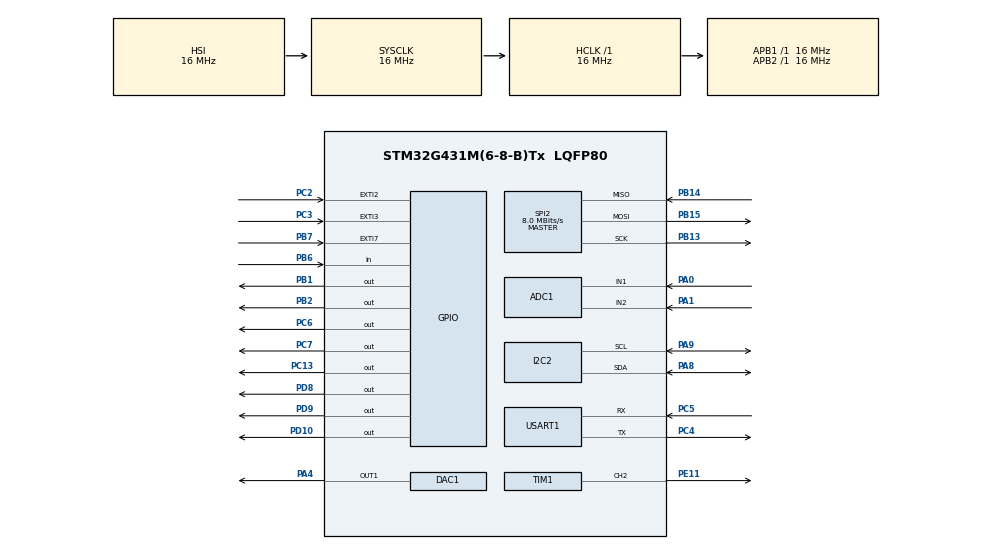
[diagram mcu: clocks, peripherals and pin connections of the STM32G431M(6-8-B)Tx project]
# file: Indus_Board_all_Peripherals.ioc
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ADC1.Channel-0\#ChannelRegularConversion=ADC_CHANNEL_1
ADC1.NbrOfConversionFlag=1
ADC1.OffsetNumber-0\#ChannelRegularConversion=ADC_OFFSET_NONE
ADC1.Rank-0\#ChannelRegularConversion=1
ADC1.SamplingTime-0\#ChannelRegularConversion=ADC_SAMPLETIME_2CYCLES_5
ADC1.master=1
Mcu.Family=STM32G4
Mcu.Name=STM32G431M(6-8-B)Tx
Mcu.Package=LQFP80
NVIC.EXTI2_IRQn=true\:0\:0\:false\:false\:true\:true\:true\:true
NVIC.EXTI3_IRQn=true\:0\:0\:false\:false\:true\:true\:true\:true
NVIC.EXTI9_5_IRQn=true\:0\:0\:false\:false\:true\:true\:true\:true
NVIC.PriorityGroup=NVIC_PRIORITYGROUP_4
NVIC.USART1_IRQn=true\:0\:0\:false\:false\:true\:true\:true\:true
PA0.Mode=IN1-Single-Ended
PA0.Signal=ADC1_IN1
PA1.Mode=IN2-Single-Ended
PA1.Signal=ADC1_IN2
PA13.Mode=JTAG_4_pins
PA13.Signal=SYS_JTMS-SWDIO
PA14.Mode=JTAG_4_pins
PA14.Signal=SYS_JTCK-SWCLK
PA15.Mode=JTAG_4_pins
PA15.Signal=SYS_JTDI
PA4.Signal=COMP_DAC11_group
PA8.Mode=I2C
PA8.Signal=I2C2_SDA
PA9.Mode=I2C
PA9.Signal=I2C2_SCL
PB1.Signal=GPIO_Output
PB13.Mode=Full_Duplex_Master
PB13.Signal=SPI2_SCK
PB14.Mode=Full_Duplex_Master
PB14.Signal=SPI2_MISO
PB15.Mode=Full_Duplex_Master
PB15.Signal=SPI2_MOSI
PB2.Signal=GPIO_Output
PB3.Mode=JTAG_4_pins
PB3.Signal=SYS_JTDO-SWO
PB6.Signal=GPIO_Input
PB7.Signal=GPXTI7
PC13.Signal=GPIO_Output
PC2.Signal=GPXTI2
PC3.Signal=GPXTI3
PC4.Mode=Asynchronous
PC4.Signal=USART1_TX
PC5.Mode=Asynchronous
PC5.Signal=USART1_RX
PC6.Signal=GPIO_Output
PC7.Signal=GPIO_Output
PD10.Signal=GPIO_Output
PD8.Signal=GPIO_Output
PD9.Signal=GPIO_Output
PE11.Signal=S_TIM1_CH2
ProjectManager.HeapSize=0x200
ProjectManager.StackSize=0x400
ProjectManager.TargetToolchain=STM32CubeIDE
RCC.AHBFreq_Value=16000000
RCC.APB1Freq_Value=16000000
RCC.APB1TimFreq_Value=16000000
RCC.APB2Freq_Value=16000000
RCC.APB2TimFreq_Value=16000000
RCC.CortexFreq_Value=16000000
RCC.EXTERNAL_CLOCK_VALUE=12288000
RCC.HCLKFreq_Value=16000000
RCC.HSE_VALUE=8000000
RCC.HSI48_VALUE=48000000
RCC.HSI_VALUE=16000000
RCC.LSE_VALUE=32768
RCC.SYSCLKFreq_VALUE=16000000
RCC.USBFreq_Value=64000000
RCC.VCOOutputFreq_Value=128000000
SH.COMP_DAC11_group.0=DAC1_OUT1,DAC_OUT1
SH.S_TIM1_CH2.0=TIM1_CH2,PWM Generation2 CH2
SPI2.CalculateBaudRate=8.0 MBits/s
SPI2.DataSize=SPI_DATASIZE_8BIT
SPI2.Direction=SPI_DIRECTION_2LINES
SPI2.Mode=SPI_MODE_MASTER
SPI2.VirtualType=VM_MASTER
TIM1.Channel-PWM\ Generation2\ CH2=TIM_CHANNEL_2
TIM16.Channel=TIM_CHANNEL_1
TIM16.OCMode_1=TIM_OCMODE_TOGGLE
TIM16.PeriodNoDither=999
TIM16.Prescaler=37000
USART1.VirtualMode-Asynchronous=VM_ASYNC
VP_SYS_VS_DBSignals.Mode=DisableDeadBatterySignals
VP_TIM16_VS_ClockSourceINT.Mode=Enable_Timer
VP_TIM16_VS_no_output1.Mode=Output Compare1 No Output
VP_TIM1_VS_ClockSourceINT.Mode=Internal
board=custom

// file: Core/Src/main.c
/* USER CODE BEGIN Header */
/**
  ******************************************************************************
  * @file           : main.c
  * @brief          : Main program body
  ******************************************************************************
  * @attention
  *
  * Copyright (c) 2023 STMicroelectronics.
  * All rights reserved.
  *
  * This software is licensed under terms that can be found in the LICENSE file
  * in the root directory of this software component.
  * If no LICENSE file comes with this software, it is provided AS-IS.
  *
  ******************************************************************************
  */
/* USER CODE END Header */
#include "main.h"
#include <stdio.h>
#include "LTR_329ALS.h"
#include "LED.h"

//#include "shtc3RH.h"

ADC_HandleTypeDef hadc1;

DAC_HandleTypeDef hdac1;

I2C_HandleTypeDef hi2c2;

SPI_HandleTypeDef hspi2;

TIM_HandleTypeDef htim1;
TIM_HandleTypeDef htim16;

UART_HandleTypeDef huart1;

/* USER CODE BEGIN PV */
char buffer[20];
uint8_t gain_data1=0;
float calibrated_data,int_fator_data1;
uint16_t ch1_rawdata,ch0_rawdata;
/* USER CODE END PV */

void SystemClock_Config(void);
static void MX_GPIO_Init(void);
static void MX_ADC1_Init(void);
static void MX_DAC1_Init(void);
static void MX_I2C2_Init(void);
static void MX_SPI2_Init(void);
static void MX_TIM1_Init(void);
static void MX_TIM16_Init(void);
static void MX_USART1_UART_Init(void);

int main(void)
{

  /* MCU Configuration--------------------------------------------------------*/

  /* Reset of all peripherals, Initializes the Flash interface and the Systick. */
  HAL_Init();

  /* Configure the system clock */
  SystemClock_Config();

  /* Initialize all configured peripherals */
  MX_GPIO_Init();
  MX_ADC1_Init();
  MX_DAC1_Init();
  MX_I2C2_Init();
  MX_SPI2_Init();
  MX_TIM1_Init();
  MX_TIM16_Init();
  MX_USART1_UART_Init();
  /* USER CODE BEGIN 2 */

  printf("\n\r*******************************************");
  printf("\n\rCENTRE FOR DEVELOPMENT OF ADVANCE COMPUTING");
  printf("\n\r*******************************************");
  printf("\n\rExperiment No:16 \n\rName: Demonstrating I2C using SHT21 Temperature");
  printf("\n\r");

  //Get i2c slave ack to check if slave is connected or not
  GetSlaveAcknowledgment();
      //Read device id of slave
  GetDeviceIDSht21();

  LTR_329ALS_Init();
  /* USER CODE END 2 */

  /* Infinite loop */
  while (1)
  {
	  GetHumidyShtc3();
//	  Read_Humidity();
	  Delay(1000);
	  GetTempratureSht21();
	  Delay(1000);

	  gain_data1 =	Get_Gain();
	  int_fator_data1 = Get_Int_Factor();
	  //Get raw sensor data from sensor
	  ch1_rawdata = Get_Raw_CH_1_Data();
	  ch0_rawdata = Get_Raw_CH_0_Data();
	  calibrated_data = Get_Calibrated_Lux_Value(ch1_rawdata,ch0_rawdata,int_fator_data1,gain_data1);
	  sprintf(buffer,"\n\rLux Value=%f\n",calibrated_data);
	  UART_TRANSMIT(&huart1,(uint8_t *)buffer,20,100);
	  Delay(1000);
//	  if(GetHumidyShtc3()<30 && GetTempratureSht21()<22){
//		  printf("Fan Off");
//	  }else if((GetHumidyShtc3()>30 && GetHumidyShtc3()<50) || (GetTempratureSht21()>22 && GetTempratureSht21()<26)){
//		  printf("Fan at 1");
//	  }else if((GetHumidyShtc3()>50 && GetHumidyShtc3()<60) || (GetTempratureSht21()>26 && GetTempratureSht21()<28)){
//		  printf("Fan at 2");
//	  }else{
//		  printf("Fan at MAX");
//	  }
//	  Delay(1000);
  }
}

void SystemClock_Config(void)
{
  RCC_OscInitTypeDef RCC_OscInitStruct = {0};
  RCC_ClkInitTypeDef RCC_ClkInitStruct = {0};

  /** Configure the main internal regulator output voltage
  */
  HAL_PWREx_ControlVoltageScaling(PWR_REGULATOR_VOLTAGE_SCALE1);

  /** Initializes the RCC Oscillators according to the specified parameters
  * in the RCC_OscInitTypeDef structure.
  */
  RCC_OscInitStruct.OscillatorType = RCC_OSCILLATORTYPE_HSI;
  RCC_OscInitStruct.HSIState = RCC_HSI_ON;
  RCC_OscInitStruct.HSICalibrationValue = RCC_HSICALIBRATION_DEFAULT;
  RCC_OscInitStruct.PLL.PLLState = RCC_PLL_NONE;
  if (HAL_RCC_OscConfig(&RCC_OscInitStruct) != HAL_OK)
  {
    Error_Handler();
  }

  /** Initializes the CPU, AHB and APB buses clocks
  */
  RCC_ClkInitStruct.ClockType = RCC_CLOCKTYPE_HCLK|RCC_CLOCKTYPE_SYSCLK
                              |RCC_CLOCKTYPE_PCLK1|RCC_CLOCKTYPE_PCLK2;
  RCC_ClkInitStruct.SYSCLKSource = RCC_SYSCLKSOURCE_HSI;
  RCC_ClkInitStruct.AHBCLKDivider = RCC_SYSCLK_DIV1;
  RCC_ClkInitStruct.APB1CLKDivider = RCC_HCLK_DIV1;
  RCC_ClkInitStruct.APB2CLKDivider = RCC_HCLK_DIV1;

  if (HAL_RCC_ClockConfig(&RCC_ClkInitStruct, FLASH_LATENCY_0) != HAL_OK)
  {
    Error_Handler();
  }
}

static void MX_ADC1_Init(void)
{

  ADC_MultiModeTypeDef multimode = {0};
  ADC_ChannelConfTypeDef sConfig = {0};

  /** Common config
  */
  hadc1.Instance = ADC1;
  hadc1.Init.ClockPrescaler = ADC_CLOCK_SYNC_PCLK_DIV2;
  hadc1.Init.Resolution = ADC_RESOLUTION_12B;
  hadc1.Init.DataAlign = ADC_DATAALIGN_RIGHT;
  hadc1.Init.GainCompensation = 0;
  hadc1.Init.ScanConvMode = ADC_SCAN_DISABLE;
  hadc1.Init.EOCSelection = ADC_EOC_SINGLE_CONV;
  hadc1.Init.LowPowerAutoWait = DISABLE;
  hadc1.Init.ContinuousConvMode = DISABLE;
  hadc1.Init.NbrOfConversion = 1;
  hadc1.Init.DiscontinuousConvMode = DISABLE;
  hadc1.Init.ExternalTrigConv = ADC_SOFTWARE_START;
  hadc1.Init.ExternalTrigConvEdge = ADC_EXTERNALTRIGCONVEDGE_NONE;
  hadc1.Init.DMAContinuousRequests = DISABLE;
  hadc1.Init.Overrun = ADC_OVR_DATA_PRESERVED;
  hadc1.Init.OversamplingMode = DISABLE;
  if (HAL_ADC_Init(&hadc1) != HAL_OK)
  {
    Error_Handler();
  }

  /** Configure the ADC multi-mode
  */
  multimode.Mode = ADC_MODE_INDEPENDENT;
  if (HAL_ADCEx_MultiModeConfigChannel(&hadc1, &multimode) != HAL_OK)
  {
    Error_Handler();
  }

  /** Configure Regular Channel
  */
  sConfig.Channel = ADC_CHANNEL_1;
  sConfig.Rank = ADC_REGULAR_RANK_1;
  sConfig.SamplingTime = ADC_SAMPLETIME_2CYCLES_5;
  sConfig.SingleDiff = ADC_SINGLE_ENDED;
  sConfig.OffsetNumber = ADC_OFFSET_NONE;
  sConfig.Offset = 0;
  if (HAL_ADC_ConfigChannel(&hadc1, &sConfig) != HAL_OK)
  {
    Error_Handler();
  }

}

static void MX_DAC1_Init(void)
{

  DAC_ChannelConfTypeDef sConfig = {0};

  /** DAC Initialization
  */
  hdac1.Instance = DAC1;
  if (HAL_DAC_Init(&hdac1) != HAL_OK)
  {
    Error_Handler();
  }

  /** DAC channel OUT1 config
  */
  sConfig.DAC_HighFrequency = DAC_HIGH_FREQUENCY_INTERFACE_MODE_AUTOMATIC;
  sConfig.DAC_DMADoubleDataMode = DISABLE;
  sConfig.DAC_SignedFormat = DISABLE;
  sConfig.DAC_SampleAndHold = DAC_SAMPLEANDHOLD_DISABLE;
  sConfig.DAC_Trigger = DAC_TRIGGER_NONE;
  sConfig.DAC_Trigger2 = DAC_TRIGGER_NONE;
  sConfig.DAC_OutputBuffer = DAC_OUTPUTBUFFER_ENABLE;
  sConfig.DAC_ConnectOnChipPeripheral = DAC_CHIPCONNECT_EXTERNAL;
  sConfig.DAC_UserTrimming = DAC_TRIMMING_FACTORY;
  if (HAL_DAC_ConfigChannel(&hdac1, &sConfig, DAC_CHANNEL_1) != HAL_OK)
  {
    Error_Handler();
  }

}

static void MX_I2C2_Init(void)
{

  hi2c2.Instance = I2C2;
  hi2c2.Init.Timing = 0x00303D5B;
  hi2c2.Init.OwnAddress1 = 0;
  hi2c2.Init.AddressingMode = I2C_ADDRESSINGMODE_7BIT;
  hi2c2.Init.DualAddressMode = I2C_DUALADDRESS_DISABLE;
  hi2c2.Init.OwnAddress2 = 0;
  hi2c2.Init.OwnAddress2Masks = I2C_OA2_NOMASK;
  hi2c2.Init.GeneralCallMode = I2C_GENERALCALL_DISABLE;
  hi2c2.Init.NoStretchMode = I2C_NOSTRETCH_DISABLE;
  if (HAL_I2C_Init(&hi2c2) != HAL_OK)
  {
    Error_Handler();
  }

  /** Configure Analogue filter
  */
  if (HAL_I2CEx_ConfigAnalogFilter(&hi2c2, I2C_ANALOGFILTER_ENABLE) != HAL_OK)
  {
    Error_Handler();
  }

  /** Configure Digital filter
  */
  if (HAL_I2CEx_ConfigDigitalFilter(&hi2c2, 0) != HAL_OK)
  {
    Error_Handler();
  }

}

static void MX_SPI2_Init(void)
{

  /* SPI2 parameter configuration*/
  hspi2.Instance = SPI2;
  hspi2.Init.Mode = SPI_MODE_MASTER;
  hspi2.Init.Direction = SPI_DIRECTION_2LINES;
  hspi2.Init.DataSize = SPI_DATASIZE_8BIT;
  hspi2.Init.CLKPolarity = SPI_POLARITY_LOW;
  hspi2.Init.CLKPhase = SPI_PHASE_1EDGE;
  hspi2.Init.NSS = SPI_NSS_SOFT;
  hspi2.Init.BaudRatePrescaler = SPI_BAUDRATEPRESCALER_2;
  hspi2.Init.FirstBit = SPI_FIRSTBIT_MSB;
  hspi2.Init.TIMode = SPI_TIMODE_DISABLE;
  hspi2.Init.CRCCalculation = SPI_CRCCALCULATION_DISABLE;
  hspi2.Init.CRCPolynomial = 7;
  hspi2.Init.CRCLength = SPI_CRC_LENGTH_DATASIZE;
  hspi2.Init.NSSPMode = SPI_NSS_PULSE_ENABLE;
  if (HAL_SPI_Init(&hspi2) != HAL_OK)
  {
    Error_Handler();
  }

}

static void MX_TIM1_Init(void)
{

  TIM_ClockConfigTypeDef sClockSourceConfig = {0};
  TIM_MasterConfigTypeDef sMasterConfig = {0};
  TIM_OC_InitTypeDef sConfigOC = {0};
  TIM_BreakDeadTimeConfigTypeDef sBreakDeadTimeConfig = {0};

  htim1.Instance = TIM1;
  htim1.Init.Prescaler = 0;
  htim1.Init.CounterMode = TIM_COUNTERMODE_UP;
  htim1.Init.Period = 65535;
  htim1.Init.ClockDivision = TIM_CLOCKDIVISION_DIV1;
  htim1.Init.RepetitionCounter = 0;
  htim1.Init.AutoReloadPreload = TIM_AUTORELOAD_PRELOAD_DISABLE;
  if (HAL_TIM_Base_Init(&htim1) != HAL_OK)
  {
    Error_Handler();
  }
  sClockSourceConfig.ClockSource = TIM_CLOCKSOURCE_INTERNAL;
  if (HAL_TIM_ConfigClockSource(&htim1, &sClockSourceConfig) != HAL_OK)
  {
    Error_Handler();
  }
  if (HAL_TIM_PWM_Init(&htim1) != HAL_OK)
  {
    Error_Handler();
  }
  sMasterConfig.MasterOutputTrigger = TIM_TRGO_RESET;
  sMasterConfig.MasterOutputTrigger2 = TIM_TRGO2_RESET;
  sMasterConfig.MasterSlaveMode = TIM_MASTERSLAVEMODE_DISABLE;
  if (HAL_TIMEx_MasterConfigSynchronization(&htim1, &sMasterConfig) != HAL_OK)
  {
    Error_Handler();
  }
  sConfigOC.OCMode = TIM_OCMODE_PWM1;
  sConfigOC.Pulse = 0;
  sConfigOC.OCPolarity = TIM_OCPOLARITY_HIGH;
  sConfigOC.OCNPolarity = TIM_OCNPOLARITY_HIGH;
  sConfigOC.OCFastMode = TIM_OCFAST_DISABLE;
  sConfigOC.OCIdleState = TIM_OCIDLESTATE_RESET;
  sConfigOC.OCNIdleState = TIM_OCNIDLESTATE_RESET;
  if (HAL_TIM_PWM_ConfigChannel(&htim1, &sConfigOC, TIM_CHANNEL_2) != HAL_OK)
  {
    Error_Handler();
  }
  sBreakDeadTimeConfig.OffStateRunMode = TIM_OSSR_DISABLE;
  sBreakDeadTimeConfig.OffStateIDLEMode = TIM_OSSI_DISABLE;
  sBreakDeadTimeConfig.LockLevel = TIM_LOCKLEVEL_OFF;
  sBreakDeadTimeConfig.DeadTime = 0;
  sBreakDeadTimeConfig.BreakState = TIM_BREAK_DISABLE;
  sBreakDeadTimeConfig.BreakPolarity = TIM_BREAKPOLARITY_HIGH;
  sBreakDeadTimeConfig.BreakFilter = 0;
  sBreakDeadTimeConfig.BreakAFMode = TIM_BREAK_AFMODE_INPUT;
  sBreakDeadTimeConfig.Break2State = TIM_BREAK2_DISABLE;
  sBreakDeadTimeConfig.Break2Polarity = TIM_BREAK2POLARITY_HIGH;
  sBreakDeadTimeConfig.Break2Filter = 0;
  sBreakDeadTimeConfig.Break2AFMode = TIM_BREAK_AFMODE_INPUT;
  sBreakDeadTimeConfig.AutomaticOutput = TIM_AUTOMATICOUTPUT_DISABLE;
  if (HAL_TIMEx_ConfigBreakDeadTime(&htim1, &sBreakDeadTimeConfig) != HAL_OK)
  {
    Error_Handler();
  }
  HAL_TIM_MspPostInit(&htim1);

}

static void MX_TIM16_Init(void)
{

  TIM_OC_InitTypeDef sConfigOC = {0};
  TIM_BreakDeadTimeConfigTypeDef sBreakDeadTimeConfig = {0};

  htim16.Instance = TIM16;
  htim16.Init.Prescaler = 37000;
  htim16.Init.CounterMode = TIM_COUNTERMODE_UP;
  htim16.Init.Period = 999;
  htim16.Init.ClockDivision = TIM_CLOCKDIVISION_DIV1;
  htim16.Init.RepetitionCounter = 0;
  htim16.Init.AutoReloadPreload = TIM_AUTORELOAD_PRELOAD_DISABLE;
  if (HAL_TIM_Base_Init(&htim16) != HAL_OK)
  {
    Error_Handler();
  }
  if (HAL_TIM_OC_Init(&htim16) != HAL_OK)
  {
    Error_Handler();
  }
  sConfigOC.OCMode = TIM_OCMODE_TOGGLE;
  sConfigOC.Pulse = 0;
  sConfigOC.OCPolarity = TIM_OCPOLARITY_HIGH;
  sConfigOC.OCNPolarity = TIM_OCNPOLARITY_HIGH;
  sConfigOC.OCFastMode = TIM_OCFAST_DISABLE;
  sConfigOC.OCIdleState = TIM_OCIDLESTATE_RESET;
  sConfigOC.OCNIdleState = TIM_OCNIDLESTATE_RESET;
  if (HAL_TIM_OC_ConfigChannel(&htim16, &sConfigOC, TIM_CHANNEL_1) != HAL_OK)
  {
    Error_Handler();
  }
  sBreakDeadTimeConfig.OffStateRunMode = TIM_OSSR_DISABLE;
  sBreakDeadTimeConfig.OffStateIDLEMode = TIM_OSSI_DISABLE;
  sBreakDeadTimeConfig.LockLevel = TIM_LOCKLEVEL_OFF;
  sBreakDeadTimeConfig.DeadTime = 0;
  sBreakDeadTimeConfig.BreakState = TIM_BREAK_DISABLE;
  sBreakDeadTimeConfig.BreakPolarity = TIM_BREAKPOLARITY_HIGH;
  sBreakDeadTimeConfig.BreakFilter = 0;
  sBreakDeadTimeConfig.AutomaticOutput = TIM_AUTOMATICOUTPUT_DISABLE;
  if (HAL_TIMEx_ConfigBreakDeadTime(&htim16, &sBreakDeadTimeConfig) != HAL_OK)
  {
    Error_Handler();
  }

}

static void MX_USART1_UART_Init(void)
{

  huart1.Instance = USART1;
  huart1.Init.BaudRate = 115200;
  huart1.Init.WordLength = UART_WORDLENGTH_8B;
  huart1.Init.StopBits = UART_STOPBITS_1;
  huart1.Init.Parity = UART_PARITY_NONE;
  huart1.Init.Mode = UART_MODE_TX_RX;
  huart1.Init.HwFlowCtl = UART_HWCONTROL_NONE;
  huart1.Init.OverSampling = UART_OVERSAMPLING_16;
  huart1.Init.OneBitSampling = UART_ONE_BIT_SAMPLE_DISABLE;
  huart1.Init.ClockPrescaler = UART_PRESCALER_DIV1;
  huart1.AdvancedInit.AdvFeatureInit = UART_ADVFEATURE_NO_INIT;
  if (HAL_UART_Init(&huart1) != HAL_OK)
  {
    Error_Handler();
  }
  if (HAL_UARTEx_SetTxFifoThreshold(&huart1, UART_TXFIFO_THRESHOLD_1_8) != HAL_OK)
  {
    Error_Handler();
  }
  if (HAL_UARTEx_SetRxFifoThreshold(&huart1, UART_RXFIFO_THRESHOLD_1_8) != HAL_OK)
  {
    Error_Handler();
  }
  if (HAL_UARTEx_DisableFifoMode(&huart1) != HAL_OK)
  {
    Error_Handler();
  }

}

static void MX_GPIO_Init(void)
{
  GPIO_InitTypeDef GPIO_InitStruct = {0};

  /* GPIO Ports Clock Enable */
  __HAL_RCC_GPIOC_CLK_ENABLE();
  __HAL_RCC_GPIOA_CLK_ENABLE();
  __HAL_RCC_GPIOB_CLK_ENABLE();
  __HAL_RCC_GPIOE_CLK_ENABLE();
  __HAL_RCC_GPIOD_CLK_ENABLE();

  /*Configure GPIO pin Output Level */
  HAL_GPIO_WritePin(GPIOC, GPIO_PIN_13|GPIO_PIN_6|GPIO_PIN_7, GPIO_PIN_RESET);

  /*Configure GPIO pin Output Level */
  HAL_GPIO_WritePin(GPIOB, GPIO_PIN_1|GPIO_PIN_2, GPIO_PIN_RESET);

  /*Configure GPIO pin Output Level */
  HAL_GPIO_WritePin(GPIOD, GPIO_PIN_8|GPIO_PIN_9|GPIO_PIN_10, GPIO_PIN_RESET);

  /*Configure GPIO pins : PC13 PC6 PC7 */
  GPIO_InitStruct.Pin = GPIO_PIN_13|GPIO_PIN_6|GPIO_PIN_7;
  GPIO_InitStruct.Mode = GPIO_MODE_OUTPUT_PP;
  GPIO_InitStruct.Pull = GPIO_NOPULL;
  GPIO_InitStruct.Speed = GPIO_SPEED_FREQ_LOW;
  HAL_GPIO_Init(GPIOC, &GPIO_InitStruct);

  /*Configure GPIO pins : PC2 PC3 */
  GPIO_InitStruct.Pin = GPIO_PIN_2|GPIO_PIN_3;
  GPIO_InitStruct.Mode = GPIO_MODE_IT_RISING;
  GPIO_InitStruct.Pull = GPIO_NOPULL;
  HAL_GPIO_Init(GPIOC, &GPIO_InitStruct);

  /*Configure GPIO pins : PB1 PB2 */
  GPIO_InitStruct.Pin = GPIO_PIN_1|GPIO_PIN_2;
  GPIO_InitStruct.Mode = GPIO_MODE_OUTPUT_PP;
  GPIO_InitStruct.Pull = GPIO_NOPULL;
  GPIO_InitStruct.Speed = GPIO_SPEED_FREQ_LOW;
  HAL_GPIO_Init(GPIOB, &GPIO_InitStruct);

  /*Configure GPIO pins : PD8 PD9 PD10 */
  GPIO_InitStruct.Pin = GPIO_PIN_8|GPIO_PIN_9|GPIO_PIN_10;
  GPIO_InitStruct.Mode = GPIO_MODE_OUTPUT_PP;
  GPIO_InitStruct.Pull = GPIO_NOPULL;
  GPIO_InitStruct.Speed = GPIO_SPEED_FREQ_LOW;
  HAL_GPIO_Init(GPIOD, &GPIO_InitStruct);

  /*Configure GPIO pin : PB6 */
  GPIO_InitStruct.Pin = GPIO_PIN_6;
  GPIO_InitStruct.Mode = GPIO_MODE_INPUT;
  GPIO_InitStruct.Pull = GPIO_NOPULL;
  HAL_GPIO_Init(GPIOB, &GPIO_InitStruct);

  /*Configure GPIO pin : PB7 */
  GPIO_InitStruct.Pin = GPIO_PIN_7;
  GPIO_InitStruct.Mode = GPIO_MODE_IT_RISING;
  GPIO_InitStruct.Pull = GPIO_NOPULL;
  HAL_GPIO_Init(GPIOB, &GPIO_InitStruct);

  /* EXTI interrupt init*/
  HAL_NVIC_SetPriority(EXTI2_IRQn, 0, 0);
  HAL_NVIC_EnableIRQ(EXTI2_IRQn);

  HAL_NVIC_SetPriority(EXTI3_IRQn, 0, 0);
  HAL_NVIC_EnableIRQ(EXTI3_IRQn);

  HAL_NVIC_SetPriority(EXTI9_5_IRQn, 0, 0);
  HAL_NVIC_EnableIRQ(EXTI9_5_IRQn);

}

void Error_Handler(void)
{
  __disable_irq();
  while (1)
  {
  }
}
